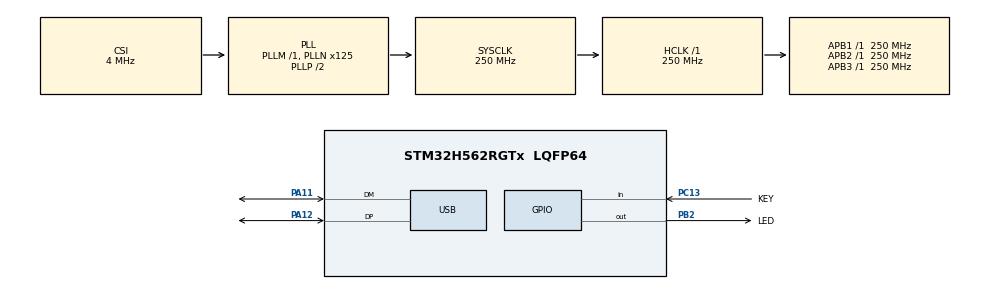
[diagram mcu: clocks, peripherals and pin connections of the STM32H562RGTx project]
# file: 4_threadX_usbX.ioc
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BOOTPATH.BootPathName=LEGACY
BOOTPATH.UserSelectedBootPath=LEGACY
CORTEX_M33_NS.userName=CORTEX_M33
CRC.InputDataFormat=CRC_INPUTDATA_FORMAT_BYTES
Mcu.Family=STM32H5
Mcu.Name=STM32H562RGTx
Mcu.Package=LQFP64
NVIC.PriorityGroup=NVIC_PRIORITYGROUP_4
NVIC.TIM6_IRQn=true\:15\:0\:false\:false\:true\:false\:false\:true\:true
NVIC.TimeBase=TIM6_IRQn
NVIC.TimeBaseIP=TIM6
NVIC.USB_DRD_FS_IRQn=true\:7\:0\:true\:false\:true\:false\:true\:true\:true
PA10.Signal=USART1_RX
PA11.Mode=Device
PA11.Signal=USB_DM
PA12.Mode=Device
PA12.Signal=USB_DP
PA13(JTMS/SWDIO).Mode=Serial_Wire
PA13(JTMS/SWDIO).Signal=DEBUG_JTMS-SWDIO
PA14(JTCK/SWCLK).Mode=Serial_Wire
PA14(JTCK/SWCLK).Signal=DEBUG_JTCK-SWCLK
PA9.Signal=USART1_TX
PB2.GPIO_Label=LED
PB2.Signal=GPIO_Output
PC13.GPIO_Label=KEY
PC13.Signal=GPIO_Input
PH0-OSC_IN(PH0).Mode=HSE-External-Oscillator
PH0-OSC_IN(PH0).Signal=RCC_OSC_IN
PH1-OSC_OUT(PH1).Mode=HSE-External-Oscillator
PH1-OSC_OUT(PH1).Signal=RCC_OSC_OUT
ProjectManager.HeapSize=0x2000
ProjectManager.StackSize=0x400
ProjectManager.TargetToolchain=EWARM V9.20
RCC.ADCFreq_Value=250000000
RCC.AHBFreq_Value=250000000
RCC.APB1Freq_Value=250000000
RCC.APB1TimFreq_Value=250000000
RCC.APB2Freq_Value=250000000
RCC.APB2TimFreq_Value=250000000
RCC.APB3Freq_Value=250000000
RCC.CSI_VALUE=4000000
RCC.CortexFreq_Value=250000000
RCC.EPOD_VALUE=4000000
RCC.HCLKFreq_Value=250000000
RCC.HSE_VALUE=8000000
RCC.HSI48_VALUE=48000000
RCC.HSI_VALUE=64000000
RCC.LSE_VALUE=32768
RCC.LSIRC_VALUE=32000
RCC.PLL2FRACN=0
RCC.PLL3FRACN=0
RCC.PLLFRACN=0
RCC.PLLN=125
RCC.SYSCLKFreq_VALUE=250000000
RCC.SYSCLKSource=RCC_SYSCLKSOURCE_PLLCLK
RCC.USBFreq_Value=48000000
RCC.VCOOutputFreq_Value=500000000
THREADX.TX_APP_MEM_POOL_SIZE=1024
USB.VirtualMode=Device_Only
USBX.BSP.number=1
USBX.Core_System=1
USBX.MAX_POWER_IN_MILLI_AMPER=500
USBX.REG_USBX_DEVICE_CON_CK=1
USBX.USBD_CDCACM_EPINCMD_ADDR=2
USBX.USBD_CDCACM_EPIN_ADDR=1
USBX.USBD_PID=22336
USBX.USBD_PRODUCT_STRING=STM32 Virtual ComPort
USBX.USBD_SERIAL_NUMBER=CDC_ACM001
USBX.USBX_DEVICE_SYS_SIZE=(1024 * 4)
USBX.UX_DEVICE_APP_MEM_POOL_SIZE=(1024 * 8)
USBX.UX_DEVICE_CDC_ACM=1
USBX.UX_DEVICE_CLASS_CDC_ACM_WRITE_AUTO_ZLP=0
USBX.UX_Device_Controller=1
USBX.UX_Device_CoreStack=1
USBX.UX_SLAVE_REQUEST_DATA_MAX_LENGTH=512
USBX0.BSP.STBoard=false
USBX0.BSP.api=Unknown
USBX0.BSP.instance=USB
USBX0.BSP.ip=USB
USBX0.BSP.mode=Device_Only
USBX0.BSP.name=USB_Device
USBX0.BSP.solution=USB
VP_BOOTPATH_VS_BOOTPATH.Mode=BP_Activate
VP_CORTEX_M33_NS_VS_Hclk.Mode=Hclk_Mode
VP_CRC_VS_CRC.Mode=CRC_Activate
VP_ICACHE_VS_ICACHE.Mode=DefaultMode
VP_MEMORYMAP_VS_MEMORYMAP.Mode=CurAppReg
VP_PWR_VS_DBSignals.Mode=DisableDeadBatterySignals
VP_PWR_VS_LPOM.Mode=PowerOptimisation
VP_PWR_VS_SECSignals.Mode=Security/Privilege
VP_SYS_VS_tim6.Mode=TIM6
VP_THREADX_VS_RTOSJjThreadXJjCoreJjDefault.Mode=Core_Default
VP_USBX_Core_System.Mode=Core_System
VP_USBX_UX\ Device\ CDC\ ACM\ Class_FS.Mode=UX_Device_class_CDC_ACM_FS
VP_USBX_UX\ Device\ Controller_FS.Mode=UX_Device_Controller_FS
VP_USBX_UX\ Device\ CoreStack_FS.Mode=UX_Device_CoreStack_FS
board=custom

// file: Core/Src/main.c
/* USER CODE BEGIN Header */
/**
  ******************************************************************************
  * @file           : main.c
  * @brief          : Main program body
  ******************************************************************************
  * @attention
  *
  * Copyright (c) 2024 STMicroelectronics.
  * All rights reserved.
  *
  * This software is licensed under terms that can be found in the LICENSE file
  * in the root directory of this software component.
  * If no LICENSE file comes with this software, it is provided AS-IS.
  *
  ******************************************************************************
  */
/* USER CODE END Header */
#include "app_threadx.h"
#include "main.h"

CRC_HandleTypeDef hcrc;

PCD_HandleTypeDef hpcd_USB_DRD_FS;

void SystemClock_Config(void);
static void MX_GPIO_Init(void);
static void MX_CRC_Init(void);
static void MX_ICACHE_Init(void);
static void MX_USB_PCD_Init(void);

int main(void)
{

  /* MCU Configuration--------------------------------------------------------*/

  /* Reset of all peripherals, Initializes the Flash interface and the Systick. */
  HAL_Init();

  /* Configure the system clock */
  SystemClock_Config();

  /* Initialize all configured peripherals */
  MX_GPIO_Init();
  MX_CRC_Init();
  MX_ICACHE_Init();
  MX_USB_PCD_Init();

  MX_ThreadX_Init();

  /* We should never get here as control is now taken by the scheduler */

  /* Infinite loop */
  while (1)
  {

  }
}

void SystemClock_Config(void)
{
  RCC_OscInitTypeDef RCC_OscInitStruct = {0};
  RCC_ClkInitTypeDef RCC_ClkInitStruct = {0};

  /** Configure the main internal regulator output voltage
  */
  __HAL_PWR_VOLTAGESCALING_CONFIG(PWR_REGULATOR_VOLTAGE_SCALE0);

  while(!__HAL_PWR_GET_FLAG(PWR_FLAG_VOSRDY)) {}

  /** Initializes the RCC Oscillators according to the specified parameters
  * in the RCC_OscInitTypeDef structure.
  */
  RCC_OscInitStruct.OscillatorType = RCC_OSCILLATORTYPE_HSI48|RCC_OSCILLATORTYPE_CSI;
  RCC_OscInitStruct.HSI48State = RCC_HSI48_ON;
  RCC_OscInitStruct.CSIState = RCC_CSI_ON;
  RCC_OscInitStruct.CSICalibrationValue = RCC_CSICALIBRATION_DEFAULT;
  RCC_OscInitStruct.PLL.PLLState = RCC_PLL_ON;
  RCC_OscInitStruct.PLL.PLLSource = RCC_PLL1_SOURCE_CSI;
  RCC_OscInitStruct.PLL.PLLM = 1;
  RCC_OscInitStruct.PLL.PLLN = 125;
  RCC_OscInitStruct.PLL.PLLP = 2;
  RCC_OscInitStruct.PLL.PLLQ = 2;
  RCC_OscInitStruct.PLL.PLLR = 2;
  RCC_OscInitStruct.PLL.PLLRGE = RCC_PLL1_VCIRANGE_2;
  RCC_OscInitStruct.PLL.PLLVCOSEL = RCC_PLL1_VCORANGE_WIDE;
  RCC_OscInitStruct.PLL.PLLFRACN = 0;
  if (HAL_RCC_OscConfig(&RCC_OscInitStruct) != HAL_OK)
  {
    Error_Handler();
  }

  /** Initializes the CPU, AHB and APB buses clocks
  */
  RCC_ClkInitStruct.ClockType = RCC_CLOCKTYPE_HCLK|RCC_CLOCKTYPE_SYSCLK
                              |RCC_CLOCKTYPE_PCLK1|RCC_CLOCKTYPE_PCLK2
                              |RCC_CLOCKTYPE_PCLK3;
  RCC_ClkInitStruct.SYSCLKSource = RCC_SYSCLKSOURCE_PLLCLK;
  RCC_ClkInitStruct.AHBCLKDivider = RCC_SYSCLK_DIV1;
  RCC_ClkInitStruct.APB1CLKDivider = RCC_HCLK_DIV1;
  RCC_ClkInitStruct.APB2CLKDivider = RCC_HCLK_DIV1;
  RCC_ClkInitStruct.APB3CLKDivider = RCC_HCLK_DIV1;

  if (HAL_RCC_ClockConfig(&RCC_ClkInitStruct, FLASH_LATENCY_5) != HAL_OK)
  {
    Error_Handler();
  }

  /** Configure the programming delay
  */
  __HAL_FLASH_SET_PROGRAM_DELAY(FLASH_PROGRAMMING_DELAY_2);
}

static void MX_CRC_Init(void)
{

  hcrc.Instance = CRC;
  hcrc.Init.DefaultPolynomialUse = DEFAULT_POLYNOMIAL_ENABLE;
  hcrc.Init.DefaultInitValueUse = DEFAULT_INIT_VALUE_ENABLE;
  hcrc.Init.InputDataInversionMode = CRC_INPUTDATA_INVERSION_NONE;
  hcrc.Init.OutputDataInversionMode = CRC_OUTPUTDATA_INVERSION_DISABLE;
  hcrc.InputDataFormat = CRC_INPUTDATA_FORMAT_BYTES;
  if (HAL_CRC_Init(&hcrc) != HAL_OK)
  {
    Error_Handler();
  }

}

static void MX_ICACHE_Init(void)
{

  /** Enable instruction cache (default 2-ways set associative cache)
  */
  if (HAL_ICACHE_Enable() != HAL_OK)
  {
    Error_Handler();
  }

}

static void MX_USB_PCD_Init(void)
{

  hpcd_USB_DRD_FS.Instance = USB_DRD_FS;
  hpcd_USB_DRD_FS.Init.dev_endpoints = 8;
  hpcd_USB_DRD_FS.Init.speed = USBD_FS_SPEED;
  hpcd_USB_DRD_FS.Init.phy_itface = PCD_PHY_EMBEDDED;
  hpcd_USB_DRD_FS.Init.Sof_enable = DISABLE;
  hpcd_USB_DRD_FS.Init.low_power_enable = DISABLE;
  hpcd_USB_DRD_FS.Init.lpm_enable = DISABLE;
  hpcd_USB_DRD_FS.Init.battery_charging_enable = DISABLE;
  hpcd_USB_DRD_FS.Init.vbus_sensing_enable = DISABLE;
  hpcd_USB_DRD_FS.Init.bulk_doublebuffer_enable = DISABLE;
  hpcd_USB_DRD_FS.Init.iso_singlebuffer_enable = DISABLE;
  if (HAL_PCD_Init(&hpcd_USB_DRD_FS) != HAL_OK)
  {
    Error_Handler();
  }

}

static void MX_GPIO_Init(void)
{
  GPIO_InitTypeDef GPIO_InitStruct = {0};

  /* GPIO Ports Clock Enable */
  __HAL_RCC_GPIOC_CLK_ENABLE();
  __HAL_RCC_GPIOH_CLK_ENABLE();
  __HAL_RCC_GPIOB_CLK_ENABLE();
  __HAL_RCC_GPIOA_CLK_ENABLE();

  /*Configure GPIO pin Output Level */
  HAL_GPIO_WritePin(LED_GPIO_Port, LED_Pin, GPIO_PIN_RESET);

  /*Configure GPIO pin : KEY_Pin */
  GPIO_InitStruct.Pin = KEY_Pin;
  GPIO_InitStruct.Mode = GPIO_MODE_INPUT;
  GPIO_InitStruct.Pull = GPIO_NOPULL;
  HAL_GPIO_Init(KEY_GPIO_Port, &GPIO_InitStruct);

  /*Configure GPIO pin : LED_Pin */
  GPIO_InitStruct.Pin = LED_Pin;
  GPIO_InitStruct.Mode = GPIO_MODE_OUTPUT_PP;
  GPIO_InitStruct.Pull = GPIO_NOPULL;
  GPIO_InitStruct.Speed = GPIO_SPEED_FREQ_LOW;
  HAL_GPIO_Init(LED_GPIO_Port, &GPIO_InitStruct);

  /*Configure GPIO pins : PA9 PA10 */
  GPIO_InitStruct.Pin = GPIO_PIN_9|GPIO_PIN_10;
  GPIO_InitStruct.Mode = GPIO_MODE_AF_PP;
  GPIO_InitStruct.Pull = GPIO_NOPULL;
  GPIO_InitStruct.Speed = GPIO_SPEED_FREQ_LOW;
  GPIO_InitStruct.Alternate = GPIO_AF7_USART1;
  HAL_GPIO_Init(GPIOA, &GPIO_InitStruct);

}

void HAL_TIM_PeriodElapsedCallback(TIM_HandleTypeDef *htim)
{
  if (htim->Instance == TIM6) {
    HAL_IncTick();
  }
}

void Error_Handler(void)
{
  /* USER CODE BEGIN Error_Handler_Debug */
	HAL_GPIO_WritePin(LED_GPIO_Port, LED_Pin, GPIO_PIN_SET);
  /* User can add his own implementation to report the HAL error return state */
  __disable_irq();
  while (1)
  {
  }
  /* USER CODE END Error_Handler_Debug */
}
